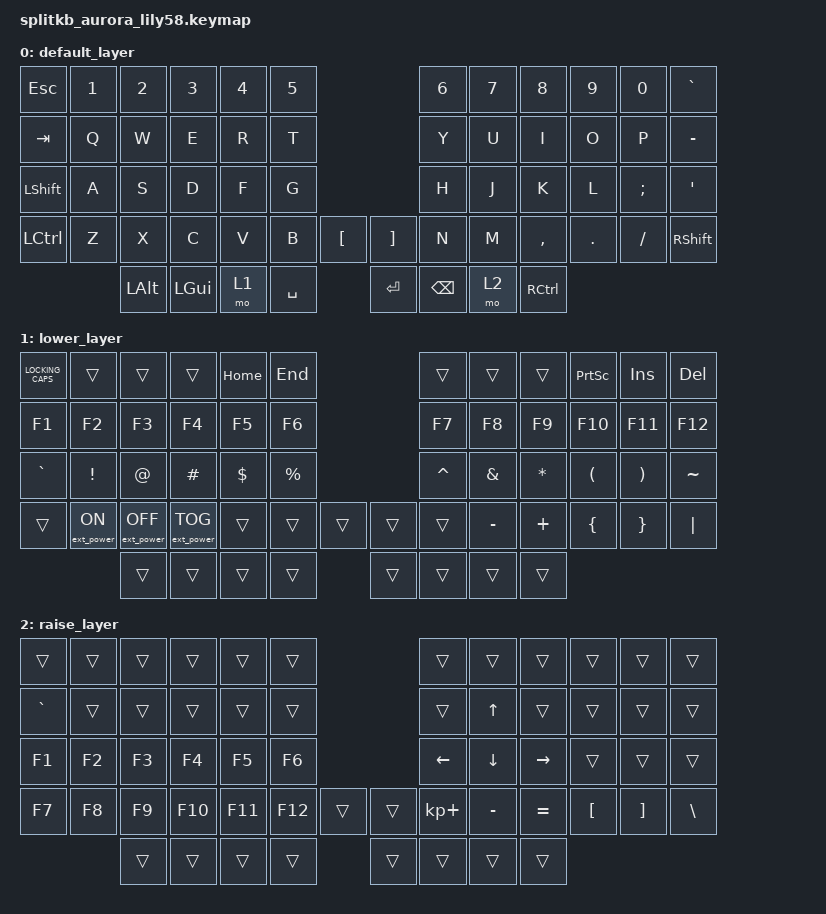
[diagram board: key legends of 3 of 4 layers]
/*
 * Copyright (c) 2022 The ZMK Contributors
 *
 * SPDX-License-Identifier: MIT
 */
#include "splitkb_aurora_lily58_left.overlay"
#include <behaviors.dtsi>
#include <dt-bindings/zmk/keys.h>
#include <dt-bindings/zmk/bt.h>
#include <dt-bindings/zmk/ext_power.h>
#include <dt-bindings/zmk/outputs.h>

/ {
    combos {
        compatible = "zmk,combo";

        adjust_combo {
            timeout-ms = <50>; // Tiempo en milisegundos para detectar la combinación
            key-positions = <&lower_layer>, <&raise_layer>; // Posiciones de las capas "lower" y "raise"
            bindings = <&mo adjust_layer>; // Activa la capa combinada "adjust_layer"
        };
    };

    keymap {
        compatible = "zmk,keymap";

        default_layer {
            // ------------------------------------------------------------------------------------------------------------
            // |  ESC  |  1  |  2  |  3   |  4   |  5   |                   |  6   |  7    |  8    |  9   |   0   |   `   |
            // |  TAB  |  Q  |  W  |  E   |  R   |  T   |                   |  Y   |  U    |  I    |  O   |   P   |   -   |
            // | LCTRL |  A  |  S  |  D   |  F   |  G   |                   |  H   |  J    |  K    |  L   |   ;   |   '   |
            // | SHIFT |  Z  |  X  |  C   |  V   |  B   |   "["  |  |  "]"  |  N   |  M    |  ,    |  .   |   /   | SHIFT |
            //                     | ALT  | GUI  | LOWER|  SPACE |  | ENTER | BSPC| RAISE  | RCTRL   |
            bindings = <
                &kp ESC   &kp N1 &kp N2 &kp N3   &kp N4   &kp N5                     &kp N6 &kp N7   &kp N8    &kp N9  &kp N0   &kp GRAVE
                &kp TAB   &kp Q  &kp W  &kp E    &kp R    &kp T                      &kp Y  &kp U    &kp I     &kp O   &kp P    &kp MINUS
                &kp LSHFT &kp A  &kp S  &kp D    &kp F    &kp G                      &kp H  &kp J    &kp K     &kp L   &kp SEMI &kp SQT
                &kp LCTRL &kp Z  &kp X  &kp C    &kp V    &kp B  &kp LBKT   &kp RBKT &kp N  &kp M    &kp COMMA &kp DOT &kp FSLH &kp RSHFT
                                    &kp LALT &kp LGUI &mo 1  &kp SPACE  &kp RET  &kp BSPC  &mo 2 &kp RCTRL
            >;

            sensor-bindings = <&inc_dec_kp C_VOL_UP C_VOL_DN>;
        };

        lower_layer {
            // ------------------------------------------------------------------------------------------------------------
            // |       |     |     |      |      |      |                   |      |       |       |      |       |       |
            // |  F1   |  F2 |  F3 |  F4  |  F5  |  F6  |                   |  F7  |  F8   |  F9   |  F10 |  F11  |  F12  |
            // |   `   |  !  |  @  |  #   |  $   |  %   |                   |  ^   |  &    |  *    |  (   |   )   |   ~   |
            // |       |     |     |      |      |      |        |  |       |      |  _    |  +    |  {   |   }   |  "|"  |
            bindings = <
                &kp LOCKING_CAPS &trans &trans  &trans  &kp HOME  &kp END           &trans    &trans    &trans          &kp PSCRN    &kp INS    &kp DEL
                &kp F1     &kp F2           &kp F3            &kp F4            &kp F5       &kp F6                       &kp F7    &kp F8    &kp F9          &kp F10   &kp F11   &kp F12
                &kp GRAVE  &kp EXCL         &kp AT            &kp HASH          &kp DOLLAR   &kp PRCNT                    &kp CARET &kp AMPS  &kp STAR         &kp LPAR  &kp RPAR  &kp TILDE
                &trans     &ext_power EP_ON &ext_power EP_OFF &ext_power EP_TOG &trans       &trans    &trans   &trans    &trans    &kp MINUS &kp PLUS        &kp LBRC  &kp RBRC  &kp PIPE
                                              &trans            &trans           &trans        &trans     &trans    &trans    &trans    &trans
            >;

            sensor-bindings = <&inc_dec_kp C_VOL_UP C_VOL_DN>;
        };

        raise_layer {
            // ------------------------------------------------------------------------------------------------------------
            // |       |     |     |      |      |      |                   |      |       |       |      |       |       |
            // |   `   |  1  |  2  |  3   |  4   |  5   |                   |  6   |   7   |   8   |  9   |   0   |       |
            // |   F1  |  F2 |  F3 |  F4  |  F5  |  F6  |                   |      |   <-  |   v   |  ^   |  ->   |       |
            // |   F7  |  F8 |  F9 |  F10 |  F11 | F12  |        |  |       |  +   |   -   |   =   |  [   |   ]   |   \   |
            bindings = <
                &trans    &trans &trans &trans  &trans  &trans                       &trans      &trans    &trans    &trans   &trans    &trans
                &kp GRAVE &trans &trans &trans  &trans  &trans                      &trans     &kp UP     &trans    &trans   &trans    &trans
                &kp F1    &kp F2 &kp F3 &kp F4  &kp F5  &kp F6                       &kp LEFT      &kp DOWN  &kp RIGHT &trans   &trans &trans
                &kp F7    &kp F8 &kp F9 &kp F10 &kp F11 &kp F12   &trans   &trans    &kp KP_PLUS &kp MINUS &kp EQUAL &kp LBKT &kp RBKT  &kp BSLH
                            &trans  &trans  &trans    &trans     &trans    &trans    &trans    &trans
            >;

            sensor-bindings = <&inc_dec_kp C_VOL_UP C_VOL_DN>;
        };

        adjust_layer {
            // ------------------------------------------------------------------------------------------------------------
            // Esta capa se activa cuando "lower" y "raise" están presionadas simultáneamente
            // Se organizan las funciones de Bluetooth en la izquierda y multimedia en la derecha.

            // ------------------------------------------------------------------------------------------------------------
            // |       |     |     |      |      |      |                   |      |       |       |      |       |       |
            // |       |     |     |      |      |      |                   |      |       |       |      |       |       |
            // |       |     |     |      |      |      |                   |      |       |       |      |       |       |
            // |       |     |     |      |      |      |                   |      |       |       |      |       |       |


            bindings = < 
                // Parte izquierda: Controles de Bluetooth
                &bt BT_CLR &bt BT_SEL 0 &bt BT_SEL 1 &bt BT_SEL 2 &bt BT_SEL 3 &bt BT_SEL 4 &trans &trans &trans &trans &trans &trans
                
                // Parte derecha: Controles multimedia
                &kp C_MUTE    &kp C_VOL_DN   &kp C_VOL_UP &kp C_PLAY_PAUSE &kp C_PREV &kp C_NEXT &trans &trans &trans &trans &trans &trans

                // Fila del centro: Todo trans
                &out OUT_USB &out OUT_BLE &out OUT_TOG &trans &trans &trans &trans &trans &trans &trans &trans &trans
                
                // Última fila: Todo trans, excepto el espacio y el retorno
                &trans            &trans           &trans        &trans     &trans    &trans    &trans    &trans
            >;
        };

    };
};
